VERSION "1.1"

NS_ :

BS_:

BU_: PCM1 FOO

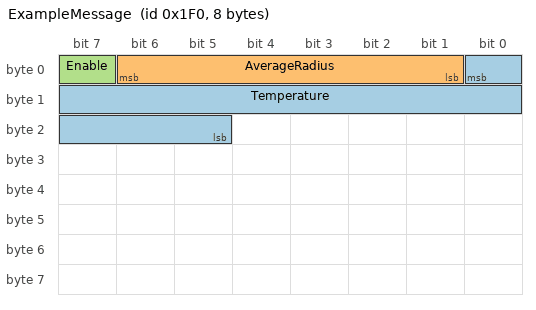
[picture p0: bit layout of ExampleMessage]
BO_ 496 ExampleMessage: 8 PCM1
 SG_ Temperature : 0|12@0- (0.01,250) [229.52|270.47] "degK"  PCM1,FOO
 SG_ AverageRadius : 6|6@0+ (0.1,0) [0|5] "m" Vector__XXX
 SG_ Enable : 7|1@0+ (1,0) [0|0] "-" Vector__XXX

BO_ 596 NewMessage: 8 Vector__XXX
 SG_ torque_table : 0|8@0+ (1,0) [0|255] "Nm" Vector__XXX

BO_ 696 AppendedMessage: 8 Vector__XXX
 SG_ eco_table : 0|8@0+ (1,0) [0|255] "Nm" Vector__XXX

CM_ BO_ 496 "Example message used as template in MotoHawk models.";
CM_ BO_ 596 "self made message";
CM_ SG_ 596 torque_table "self made signal";
CM_ BO_ 696 "self made message";
CM_ SG_ 696 eco_table "self made signal";

VAL_ 496 Enable 0 "Disabled" 1 "Enabled" ;
